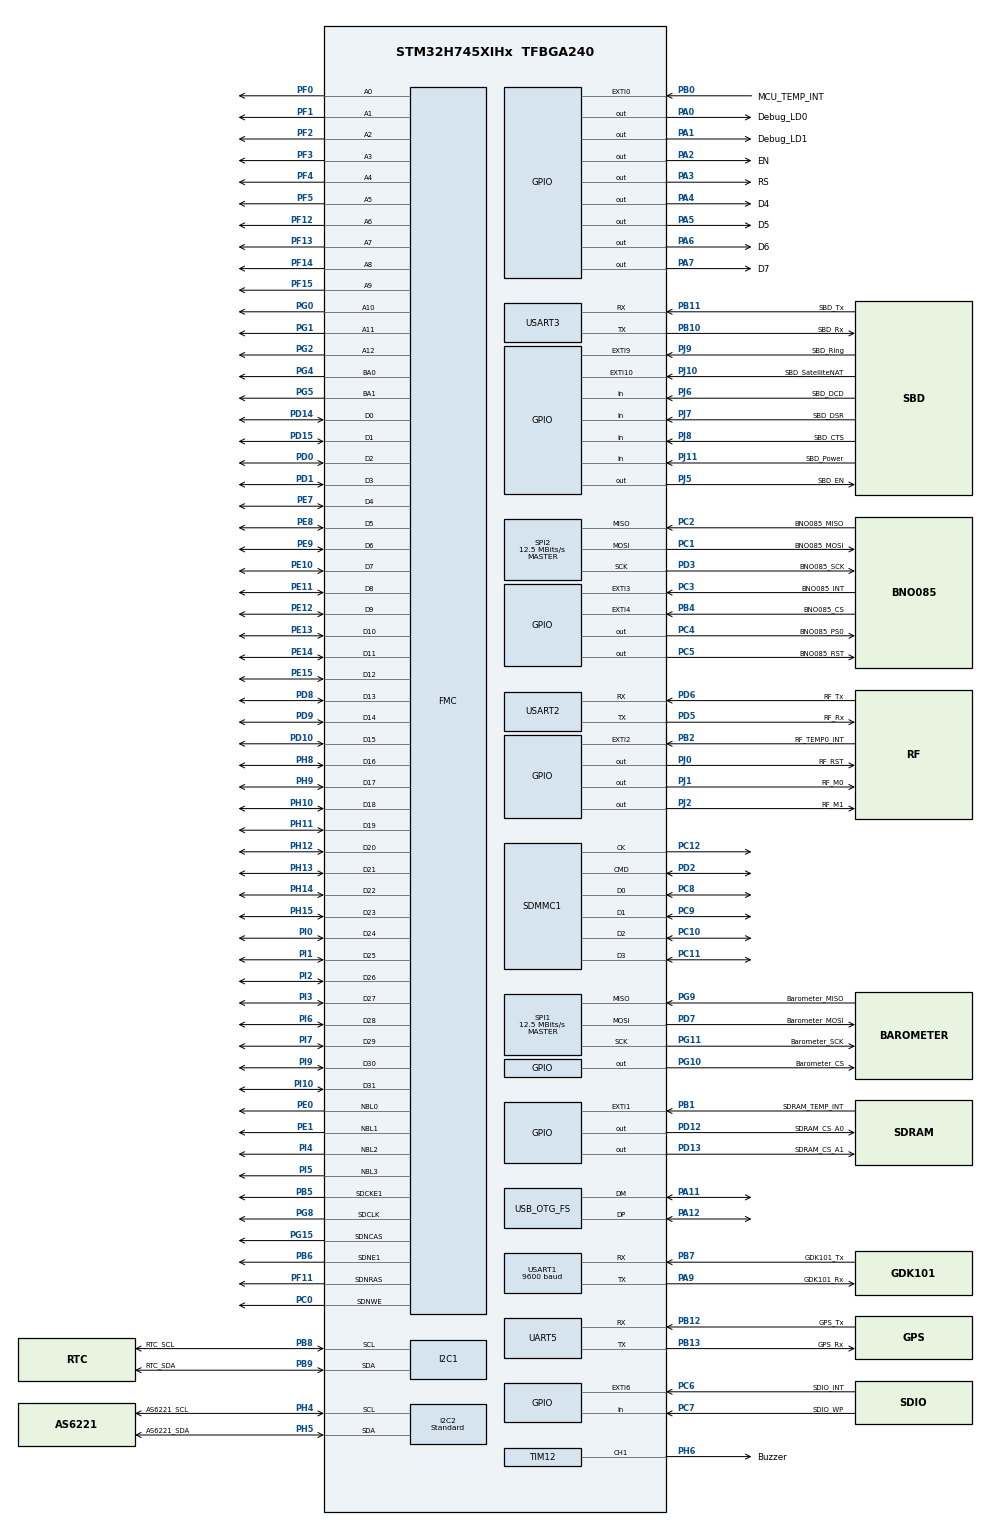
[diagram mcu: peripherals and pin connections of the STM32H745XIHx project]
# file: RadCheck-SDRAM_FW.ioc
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ADC3.Channel-0\#ChannelRegularConversion=ADC_CHANNEL_TEMPSENSOR
ADC3.ClockPrescalerADC3=ADC_CLOCK_ASYNC_DIV4
ADC3.ContinuousConvMode=ENABLE
ADC3.NbrOfConversionFlag=1
ADC3.OffsetNumber-0\#ChannelRegularConversion=ADC_OFFSET_NONE
ADC3.OffsetSignedSaturation-0\#ChannelRegularConversion=DISABLE
ADC3.Rank-0\#ChannelRegularConversion=1
ADC3.SamplingTime-0\#ChannelRegularConversion=ADC_SAMPLETIME_387CYCLES_5
CORTEX_M7.CPU_DCache=Disabled
CORTEX_M7.CPU_ICache=Disabled
CORTEX_M7.MPU_Control=__NULL
CORTEX_M7.default_mode_Activation=1
CortexM4.IPs=BDMA,CORTEX_M4\:I,DMA,FATFS_M4\:I,FREERTOS_M4\:I,GPIO,IWDG2\:I,MDMA,NVIC2\:I,OPENAMP_M4\:I,PDM2PCM_M4\:I,PWR,RCC,RESMGR_UTILITY,SYS_M4\:I,USB_DEVICE_M4\:I,USB_HOST_M4\:I,VREFBUF,WWDG2\:I
CortexM7.IPs=BDMA\:I,CORTEX_M7\:I,DMA\:I,FATFS_M7\:I,FREERTOS_M7\:I,GPIO\:I,IWDG1\:I,MDMA\:I,NVIC1\:I,OPENAMP_M7\:I,PDM2PCM_M7\:I,PWR\:I,RCC\:I,RESMGR_UTILITY\:I,SYS\:I,USB_DEVICE_M7\:I,USB_HOST_M7\:I,VREFBUF\:I,WWDG1\:I,MEMORYMAP\:I,DEBUG\:I,USART1\:I,I2C1\:I,SDMMC1\:I,USB_OTG_FS\:I,SPI2\:I,USART2\:I,SPI1\:I,I2C2\:I,FMC\:I,UART5\:I,USART3\:I,TIM12\:I,TIM1\:I,ADC3\:I
CortexM7.Pins=PA2,PA1,PA0,PJ0,PJ1,PA6,PA7,PD12,PD13,PA5,PJ2,PA3,PA4
FATFS_M7.USE_DMA_CODE_SD=1
FATFS_M7._MAX_SS=4096
FATFS_M7._USE_LFN=1
FMC.CASLatency1=FMC_SDRAM_CAS_LATENCY_3
FMC.ColumnBitsNumber1=FMC_SDRAM_COLUMN_BITS_NUM_9
FMC.ExitSelfRefreshDelay1=7
FMC.LoadToActiveDelay1=2
FMC.RCDDelay1=2
FMC.RPDelay1=2
FMC.RPDelay2=2
FMC.ReadBurst1=FMC_SDRAM_RBURST_ENABLE
FMC.ReadBurst2=FMC_SDRAM_RBURST_ENABLE
FMC.RowCycleDelay1=6
FMC.RowCycleDelay2=6
FMC.SDClockPeriod1=FMC_SDRAM_CLOCK_PERIOD_2
FMC.SDClockPeriod2=FMC_SDRAM_CLOCK_PERIOD_2
FMC.SelfRefreshTime1=5
FMC.WriteRecoveryTime1=3
I2C1.Timing=0x10C0ECFF
I2C2.I2C_Speed_Mode=I2C_Standard
I2C2.Timing=0x10C0ECFF
Mcu.Family=STM32H7
Mcu.Name=STM32H745XIHx
Mcu.Package=TFBGA240
NVIC1.OTG_FS_IRQn=true\:0\:0\:false\:false\:true\:false\:true\:true
NVIC1.PriorityGroup=NVIC_PRIORITYGROUP_4
NVIC1.SDMMC1_IRQn=true\:0\:0\:false\:true\:true\:1\:true\:true\:true
NVIC2.PriorityGroup=NVIC_PRIORITYGROUP_4
PA0.GPIO_Label=Debug_LD0
PA0.GPIO_Speed=GPIO_SPEED_FREQ_VERY_HIGH
PA0.PinAttribute=CortexM7
PA0.PinState=GPIO_PIN_SET
PA0.Signal=GPIO_Output
PA1.GPIO_Label=Debug_LD1
PA1.GPIO_Speed=GPIO_SPEED_FREQ_VERY_HIGH
PA1.PinAttribute=CortexM7
PA1.PinState=GPIO_PIN_SET
PA1.Signal=GPIO_Output
PA11.GPIO_Speed=GPIO_SPEED_FREQ_VERY_HIGH
PA11.Mode=Device_Only
PA11.PinAttribute=CortexM7
PA11.Signal=USB_OTG_FS_DM
PA12.GPIO_PuPd=GPIO_PULLUP
PA12.GPIO_Speed=GPIO_SPEED_FREQ_VERY_HIGH
PA12.Mode=Device_Only
PA12.PinAttribute=CortexM7
PA12.Signal=USB_OTG_FS_DP
PA13\ (JTMS/SWDIO).Mode=Serial_Wire
PA13\ (JTMS/SWDIO).PinAttribute=CortexM7
PA13\ (JTMS/SWDIO).Signal=DEBUG_JTMS-SWDIO
PA14\ (JTCK/SWCLK).Mode=Serial_Wire
PA14\ (JTCK/SWCLK).PinAttribute=CortexM7
PA14\ (JTCK/SWCLK).Signal=DEBUG_JTCK-SWCLK
PA2.GPIO_Label=EN
PA2.PinAttribute=CortexM7
PA2.Signal=GPIO_Output
PA3.GPIO_Label=RS
PA3.PinAttribute=CortexM7
PA3.Signal=GPIO_Output
PA4.GPIO_Label=D4
PA4.PinAttribute=CortexM7
PA4.Signal=GPIO_Output
PA5.GPIO_Label=D5
PA5.PinAttribute=CortexM7
PA5.Signal=GPIO_Output
PA6.GPIO_Label=D6
PA6.PinAttribute=CortexM7
PA6.Signal=GPIO_Output
PA7.GPIO_Label=D7
PA7.PinAttribute=CortexM7
PA7.Signal=GPIO_Output
PA9.GPIO_Label=GDK101_Rx
PA9.Mode=Asynchronous
PA9.PinAttribute=CortexM7
PA9.Signal=USART1_TX
PB0.GPIO_Label=MCU_TEMP_INT
PB0.PinAttribute=Free
PB0.Signal=GPXTI0
PB1.GPIO_Label=SDRAM_TEMP_INT
PB1.PinAttribute=Free
PB1.Signal=GPXTI1
PB10.GPIO_Label=SBD_Rx
PB10.Mode=Asynchronous
PB10.PinAttribute=CortexM7
PB10.Signal=USART3_TX
PB11.GPIO_Label=SBD_Tx
PB11.Mode=Asynchronous
PB11.PinAttribute=CortexM7
PB11.Signal=USART3_RX
PB12.GPIO_Label=GPS_Tx
PB12.Mode=Asynchronous
PB12.PinAttribute=CortexM7
PB12.Signal=UART5_RX
PB13.GPIO_Label=GPS_Rx
PB13.Mode=Asynchronous
PB13.PinAttribute=CortexM7
PB13.Signal=UART5_TX
PB2.GPIO_Label=RF_TEMP0_INT
PB2.PinAttribute=Free
PB2.Signal=GPXTI2
PB4\ (NJTRST).GPIO_Label=BNO085_CS
PB4\ (NJTRST).PinAttribute=Free
PB4\ (NJTRST).Signal=GPXTI4
PB5.Mode=SdramChipSelect2_1
PB5.PinAttribute=CortexM7
PB5.Signal=FMC_SDCKE1
PB6.Mode=SdramChipSelect2_1
PB6.PinAttribute=CortexM7
PB6.Signal=FMC_SDNE1
PB7.GPIO_Label=GDK101_Tx
PB7.Mode=Asynchronous
PB7.PinAttribute=CortexM7
PB7.Signal=USART1_RX
PB8.GPIO_Label=RTC_SCL
PB8.Mode=I2C
PB8.PinAttribute=CortexM7
PB8.Signal=I2C1_SCL
PB9.GPIO_Label=RTC_SDA
PB9.Mode=I2C
PB9.PinAttribute=CortexM7
PB9.Signal=I2C1_SDA
PC0.PinAttribute=CortexM7
PC0.Signal=FMC_SDNWE
PC1.GPIO_Label=BNO085_MOSI
PC1.Mode=Full_Duplex_Master
PC1.PinAttribute=CortexM7
PC1.Signal=SPI2_MOSI
PC10.Mode=SD_4_bits_Wide_bus
PC10.PinAttribute=CortexM7
PC10.Signal=SDMMC1_D2
PC11.Mode=SD_4_bits_Wide_bus
PC11.PinAttribute=CortexM7
PC11.Signal=SDMMC1_D3
PC12.Mode=SD_4_bits_Wide_bus
PC12.PinAttribute=CortexM7
PC12.Signal=SDMMC1_CK
PC2.GPIO_Label=BNO085_MISO
PC2.Mode=Full_Duplex_Master
PC2.PinAttribute=CortexM7
PC2.Signal=SPI2_MISO
PC3.GPIO_Label=BNO085_INT
PC3.PinAttribute=Free
PC3.Signal=GPXTI3
PC4.GPIO_Label=BNO085_PS0
PC4.PinAttribute=Free
PC4.Signal=GPIO_Output
PC5.GPIO_Label=BNO085_RST
PC5.PinAttribute=Free
PC5.Signal=GPIO_Output
PC6.GPIO_Label=SDIO_INT
PC6.PinAttribute=Free
PC6.Signal=GPXTI6
PC7.GPIO_Label=SDIO_WP
PC7.PinAttribute=Free
PC7.Signal=GPIO_Input
PC8.Mode=SD_4_bits_Wide_bus
PC8.PinAttribute=CortexM7
PC8.Signal=SDMMC1_D0
PC9.Mode=SD_4_bits_Wide_bus
PC9.PinAttribute=CortexM7
PC9.Signal=SDMMC1_D1
PD0.PinAttribute=CortexM7
PD0.Signal=FMC_D2_DA2
PD1.PinAttribute=CortexM7
PD1.Signal=FMC_D3_DA3
PD10.PinAttribute=CortexM7
PD10.Signal=FMC_D15_DA15
PD12.GPIO_Label=SDRAM_CS_A0
PD12.GPIO_Speed=GPIO_SPEED_FREQ_VERY_HIGH
PD12.PinAttribute=CortexM7
PD12.PinState=GPIO_PIN_SET
PD12.Signal=GPIO_Output
PD13.GPIO_Label=SDRAM_CS_A1
PD13.GPIO_Speed=GPIO_SPEED_FREQ_VERY_HIGH
PD13.PinAttribute=CortexM7
PD13.PinState=GPIO_PIN_SET
PD13.Signal=GPIO_Output
PD14.PinAttribute=CortexM7
PD14.Signal=FMC_D0_DA0
PD15.PinAttribute=CortexM7
PD15.Signal=FMC_D1_DA1
PD2.Mode=SD_4_bits_Wide_bus
PD2.PinAttribute=CortexM7
PD2.Signal=SDMMC1_CMD
PD3.GPIO_Label=BNO085_SCK
PD3.Mode=Full_Duplex_Master
PD3.PinAttribute=CortexM7
PD3.Signal=SPI2_SCK
PD5.GPIO_Label=RF_Rx
PD5.Mode=Asynchronous
PD5.PinAttribute=CortexM7
PD5.Signal=USART2_TX
PD6.GPIO_Label=RF_Tx
PD6.Mode=Asynchronous
PD6.PinAttribute=CortexM7
PD6.Signal=USART2_RX
PD7.GPIO_Label=Barometer_MOSI
PD7.Mode=Full_Duplex_Master
PD7.PinAttribute=CortexM7
PD7.Signal=SPI1_MOSI
PD8.PinAttribute=CortexM7
PD8.Signal=FMC_D13_DA13
PD9.PinAttribute=CortexM7
PD9.Signal=FMC_D14_DA14
PE0.PinAttribute=CortexM7
PE0.Signal=FMC_NBL0
PE1.PinAttribute=CortexM7
PE1.Signal=FMC_NBL1
PE10.PinAttribute=CortexM7
PE10.Signal=FMC_D7_DA7
PE11.PinAttribute=CortexM7
PE11.Signal=FMC_D8_DA8
PE12.PinAttribute=CortexM7
PE12.Signal=FMC_D9_DA9
PE13.PinAttribute=CortexM7
PE13.Signal=FMC_D10_DA10
PE14.PinAttribute=CortexM7
PE14.Signal=FMC_D11_DA11
PE15.PinAttribute=CortexM7
PE15.Signal=FMC_D12_DA12
PE7.PinAttribute=CortexM7
PE7.Signal=FMC_D4_DA4
PE8.PinAttribute=CortexM7
PE8.Signal=FMC_D5_DA5
PE9.PinAttribute=CortexM7
PE9.Signal=FMC_D6_DA6
PF0.PinAttribute=CortexM7
PF0.Signal=FMC_A0
PF1.PinAttribute=CortexM7
PF1.Signal=FMC_A1
PF11.PinAttribute=CortexM7
PF11.Signal=FMC_SDNRAS
PF12.PinAttribute=CortexM7
PF12.Signal=FMC_A6
PF13.PinAttribute=CortexM7
PF13.Signal=FMC_A7
PF14.PinAttribute=CortexM7
PF14.Signal=FMC_A8
PF15.PinAttribute=CortexM7
PF15.Signal=FMC_A9
PF2.PinAttribute=CortexM7
PF2.Signal=FMC_A2
PF3.PinAttribute=CortexM7
PF3.Signal=FMC_A3
PF4.PinAttribute=CortexM7
PF4.Signal=FMC_A4
PF5.PinAttribute=CortexM7
PF5.Signal=FMC_A5
PG0.PinAttribute=CortexM7
PG0.Signal=FMC_A10
PG1.PinAttribute=CortexM7
PG1.Signal=FMC_A11
PG10.GPIO_Label=Barometer_CS
PG10.PinAttribute=Free
PG10.Signal=GPIO_Output
PG11.GPIO_Label=Barometer_SCK
PG11.Mode=Full_Duplex_Master
PG11.PinAttribute=CortexM7
PG11.Signal=SPI1_SCK
PG15.PinAttribute=CortexM7
PG15.Signal=FMC_SDNCAS
PG2.PinAttribute=CortexM7
PG2.Signal=FMC_A12
PG4.PinAttribute=CortexM7
PG4.Signal=FMC_A14_BA0
PG5.PinAttribute=CortexM7
PG5.Signal=FMC_A15_BA1
PG8.PinAttribute=CortexM7
PG8.Signal=FMC_SDCLK
PG9.GPIO_Label=Barometer_MISO
PG9.Mode=Full_Duplex_Master
PG9.PinAttribute=CortexM7
PG9.Signal=SPI1_MISO
PH0-OSC_IN\ (PH0).Mode=HSE-External-Oscillator
PH0-OSC_IN\ (PH0).PinAttribute=Free
PH0-OSC_IN\ (PH0).Signal=RCC_OSC_IN
PH1-OSC_OUT\ (PH1).Mode=HSE-External-Oscillator
PH1-OSC_OUT\ (PH1).PinAttribute=Free
PH1-OSC_OUT\ (PH1).Signal=RCC_OSC_OUT
PH10.PinAttribute=CortexM7
PH10.Signal=FMC_D18
PH11.PinAttribute=CortexM7
PH11.Signal=FMC_D19
PH12.PinAttribute=CortexM7
PH12.Signal=FMC_D20
PH13.PinAttribute=CortexM7
PH13.Signal=FMC_D21
PH14.PinAttribute=CortexM7
PH14.Signal=FMC_D22
PH15.PinAttribute=CortexM7
PH15.Signal=FMC_D23
PH4.GPIO_Label=AS6221_SCL
PH4.Mode=I2C
PH4.PinAttribute=CortexM7
PH4.Signal=I2C2_SCL
PH5.GPIO_Label=AS6221_SDA
PH5.Mode=I2C
PH5.PinAttribute=CortexM7
PH5.Signal=I2C2_SDA
PH6.GPIO_Label=Buzzer
PH6.PinAttribute=CortexM7
PH6.Signal=S_TIM12_CH1
PH8.PinAttribute=CortexM7
PH8.Signal=FMC_D16
PH9.PinAttribute=CortexM7
PH9.Signal=FMC_D17
PI0.PinAttribute=CortexM7
PI0.Signal=FMC_D24
PI1.PinAttribute=CortexM7
PI1.Signal=FMC_D25
PI10.PinAttribute=CortexM7
PI10.Signal=FMC_D31
PI2.PinAttribute=CortexM7
PI2.Signal=FMC_D26
PI3.PinAttribute=CortexM7
PI3.Signal=FMC_D27
PI4.PinAttribute=CortexM7
PI4.Signal=FMC_NBL2
PI5.PinAttribute=CortexM7
PI5.Signal=FMC_NBL3
PI6.PinAttribute=CortexM7
PI6.Signal=FMC_D28
PI7.PinAttribute=CortexM7
PI7.Signal=FMC_D29
PI9.PinAttribute=CortexM7
PI9.Signal=FMC_D30
PJ0.GPIO_Label=RF_RST
PJ0.PinAttribute=CortexM7
PJ0.Signal=GPIO_Output
PJ1.GPIO_Label=RF_M0
PJ1.PinAttribute=CortexM7
PJ1.Signal=GPIO_Output
PJ10.GPIO_Label=SBD_SatelliteNAT
PJ10.PinAttribute=Free
PJ10.Signal=GPXTI10
PJ11.GPIO_Label=SBD_Power
PJ11.PinAttribute=Free
PJ11.Signal=GPIO_Input
PJ2.GPIO_Label=RF_M1
PJ2.PinAttribute=CortexM7
PJ2.Signal=GPIO_Output
PJ5.GPIO_Label=SBD_EN
PJ5.PinAttribute=Free
PJ5.Signal=GPIO_Output
PJ6.GPIO_Label=SBD_DCD
PJ6.PinAttribute=Free
PJ6.Signal=GPIO_Input
PJ7.GPIO_Label=SBD_DSR
PJ7.PinAttribute=Free
PJ7.Signal=GPIO_Input
PJ8.GPIO_Label=SBD_CTS
PJ8.PinAttribute=Free
PJ8.Signal=GPIO_Input
PJ9.GPIO_Label=SBD_Ring
PJ9.PinAttribute=Free
PJ9.Signal=GPXTI9
ProjectManager.HeapSize=M4-0x200,M7-0x200
ProjectManager.StackSize=M4-0x400,M7-0x400
ProjectManager.TargetToolchain=STM32CubeIDE
RCC.ADCFreq_Value=78000000
RCC.APB1Freq_Value=100000000
RCC.APB2Freq_Value=100000000
RCC.APB3Freq_Value=100000000
RCC.APB4Freq_Value=100000000
RCC.CortexFreq_Value=400000000
RCC.D1PPRE=RCC_APB3_DIV2
RCC.D2PPRE1=RCC_APB1_DIV2
RCC.D2PPRE2=RCC_APB2_DIV2
RCC.D3PPRE=RCC_APB4_DIV2
RCC.DIVM1=3
RCC.DIVM2=1
RCC.DIVN1=200
RCC.DIVN2=13
RCC.DIVQ1=4
RCC.HCLKFreq_Value=200000000
RCC.HPRE=RCC_HCLK_DIV2
RCC.HSE_VALUE=12000000
RCC.PLL2FRACN=0
RCC.PLL3FRACN=0
RCC.PLLFRACN=0
RCC.PLLSourceVirtual=RCC_PLLSOURCE_HSE
RCC.PWR_Regulator_Voltage_Scale=PWR_REGULATOR_VOLTAGE_SCALE0
RCC.SYSCLKFreq_VALUE=400000000
RCC.SYSCLKSource=RCC_SYSCLKSOURCE_PLLCLK
RCC.SupplySource=PWR_LDO_SUPPLY
RCC.USBCLockSelection=RCC_USBCLKSOURCE_HSI48
RCC.USBFreq_Value=48000000
SH.FMC_A0.0=FMC_A0,13b-sda1
SH.FMC_A1.0=FMC_A1,13b-sda1
SH.FMC_A10.0=FMC_A10,13b-sda1
SH.FMC_A11.0=FMC_A11,13b-sda1
SH.FMC_A12.0=FMC_A12,13b-sda1
SH.FMC_A14_BA0.0=FMC_BA0,FourSdramBanks1
SH.FMC_A15_BA1.0=FMC_BA1,FourSdramBanks1
SH.FMC_A2.0=FMC_A2,13b-sda1
SH.FMC_A3.0=FMC_A3,13b-sda1
SH.FMC_A4.0=FMC_A4,13b-sda1
SH.FMC_A5.0=FMC_A5,13b-sda1
SH.FMC_A6.0=FMC_A6,13b-sda1
SH.FMC_A7.0=FMC_A7,13b-sda1
SH.FMC_A8.0=FMC_A8,13b-sda1
SH.FMC_A9.0=FMC_A9,13b-sda1
SH.FMC_D0_DA0.0=FMC_D0,sd-32b-d1
SH.FMC_D10_DA10.0=FMC_D10,sd-32b-d1
SH.FMC_D11_DA11.0=FMC_D11,sd-32b-d1
SH.FMC_D12_DA12.0=FMC_D12,sd-32b-d1
SH.FMC_D13_DA13.0=FMC_D13,sd-32b-d1
SH.FMC_D14_DA14.0=FMC_D14,sd-32b-d1
SH.FMC_D15_DA15.0=FMC_D15,sd-32b-d1
SH.FMC_D16.0=FMC_D16,sd-32b-d1
SH.FMC_D17.0=FMC_D17,sd-32b-d1
SH.FMC_D18.0=FMC_D18,sd-32b-d1
SH.FMC_D19.0=FMC_D19,sd-32b-d1
SH.FMC_D1_DA1.0=FMC_D1,sd-32b-d1
SH.FMC_D20.0=FMC_D20,sd-32b-d1
SH.FMC_D21.0=FMC_D21,sd-32b-d1
SH.FMC_D22.0=FMC_D22,sd-32b-d1
SH.FMC_D23.0=FMC_D23,sd-32b-d1
SH.FMC_D24.0=FMC_D24,sd-32b-d1
SH.FMC_D25.0=FMC_D25,sd-32b-d1
SH.FMC_D26.0=FMC_D26,sd-32b-d1
SH.FMC_D27.0=FMC_D27,sd-32b-d1
SH.FMC_D28.0=FMC_D28,sd-32b-d1
SH.FMC_D29.0=FMC_D29,sd-32b-d1
SH.FMC_D2_DA2.0=FMC_D2,sd-32b-d1
SH.FMC_D30.0=FMC_D30,sd-32b-d1
SH.FMC_D31.0=FMC_D31,sd-32b-d1
SH.FMC_D3_DA3.0=FMC_D3,sd-32b-d1
SH.FMC_D4_DA4.0=FMC_D4,sd-32b-d1
SH.FMC_D5_DA5.0=FMC_D5,sd-32b-d1
SH.FMC_D6_DA6.0=FMC_D6,sd-32b-d1
SH.FMC_D7_DA7.0=FMC_D7,sd-32b-d1
SH.FMC_D8_DA8.0=FMC_D8,sd-32b-d1
SH.FMC_D9_DA9.0=FMC_D9,sd-32b-d1
SH.FMC_NBL0.0=FMC_NBL0,Sd4ByteEnable1
SH.FMC_NBL1.0=FMC_NBL1,Sd4ByteEnable1
SH.FMC_NBL2.0=FMC_NBL2,Sd4ByteEnable1
SH.FMC_NBL3.0=FMC_NBL3,Sd4ByteEnable1
SH.FMC_SDCLK.0=FMC_SDCLK,13b-sda1
SH.FMC_SDNCAS.0=FMC_SDNCAS,13b-sda1
SH.FMC_SDNRAS.0=FMC_SDNRAS,13b-sda1
SH.FMC_SDNWE.0=FMC_SDNWE,13b-sda1
SH.S_TIM12_CH1.0=TIM12_CH1,PWM Generation1 CH1
SPI1.BaudRatePrescaler=SPI_BAUDRATEPRESCALER_16
SPI1.CalculateBaudRate=12.5 MBits/s
SPI1.Direction=SPI_DIRECTION_2LINES
SPI1.Mode=SPI_MODE_MASTER
SPI1.VirtualType=VM_MASTER
SPI2.BaudRatePrescaler=SPI_BAUDRATEPRESCALER_16
SPI2.CalculateBaudRate=12.5 MBits/s
SPI2.Direction=SPI_DIRECTION_2LINES
SPI2.Mode=SPI_MODE_MASTER
SPI2.VirtualType=VM_MASTER
SYS.userName=SYS_M7
TIM1.Prescaler=399
TIM12.Channel-PWM\ Generation1\ CH1=TIM_CHANNEL_1
TIM12.Period=1000
TIM12.Prescaler=199
TIM12.Pulse-PWM\ Generation1\ CH1=10
USART1.BaudRate=9600
USART1.VirtualMode-Asynchronous=VM_ASYNC
USART2.VirtualMode-Asynchronous=VM_ASYNC
USART3.VirtualMode-Asynchronous=VM_ASYNC
USB_DEVICE_M7.CLASS_NAME_FS=CDC
USB_DEVICE_M7.VirtualMode-CDC_FS=Cdc
USB_DEVICE_M7.VirtualModeFS=Cdc_FS
USB_OTG_FS.VirtualMode=Device_Only
VP_ADC3_TempSens_Input.Mode=IN-TempSens
VP_FATFS_M7_VS_SDIO.Mode=SDIO
VP_MEMORYMAP_VS_MEMORYMAP.Mode=CurAppReg
VP_SYS_M4_VS_Systick.Mode=SysTick
VP_TIM12_VS_ClockSourceINT.Mode=Internal
VP_TIM1_VS_ClockSourceINT.Mode=Internal
VP_USB_DEVICE_M7_VS_USB_DEVICE_CDC_FS.Mode=CDC_FS
board=custom

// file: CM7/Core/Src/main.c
/* USER CODE BEGIN Header */
/**
  ******************************************************************************
  * @file           : main.c
  * @brief          : Main program body
  ******************************************************************************
  * @attention
  *
  * Copyright (c) 2025 STMicroelectronics.
  * All rights reserved.
  *
  * This software is licensed under terms that can be found in the LICENSE file
  * in the root directory of this software component.
  * If no LICENSE file comes with this software, it is provided AS-IS.
  *
  ******************************************************************************
  */
/* USER CODE END Header */
#include "main.h"
#include "adc.h"
#include "fatfs.h"
#include "i2c.h"
#include "memorymap.h"
#include "sdmmc.h"
#include "spi.h"
#include "tim.h"
#include "usart.h"
#include "usb_device.h"
#include "gpio.h"
#include "fmc.h"

/* USER CODE BEGIN Includes */
#include "stdio.h"
#include "string.h"
#include "stdarg.h"
#include "AS6221.h"
#include "CLCD.h"
#include "INA219.h"

/* USER CODE END Includes */

/* USER CODE BEGIN PD */
#define AS6221_MCU_ADDR 0x48 << 1
#define AS6221_SDRAM_ADDR 0x49 << 1
#define AS6221_RF1_ADDR 0x4A << 1
#define AS6221_RF2_ADDR 0x4B << 1

#define NUM_SENSORS	4

#ifndef HSEM_ID_0
#define HSEM_ID_0 (0U) /* HW semaphore 0*/
#endif

/* USER CODE END PD */

/* USER CODE BEGIN PM */
int _write(int file, char *ptr, int len){
    CDC_Transmit_FS(ptr, len);
    return (len);
}

/* USER CODE END PM */

/* USER CODE BEGIN PV */
extern SDRAM_HandleTypeDef hsdram1;
#define SDRAM_DEVICE_ADDR  ((uint32_t)0xD0000000)
#define SDRAM_DEVICE_SIZE  (0x02000000)   /* 32 MB */
#define TEST_BUF_WORDS     256

static uint32_t txBuf[TEST_BUF_WORDS];
static uint32_t rxBuf[TEST_BUF_WORDS];
/* USER CODE END PV */

void SystemClock_Config(void);
static void MX_NVIC_Init(void);

/* USER CODE BEGIN 0 */

void BSP_SDRAM_Init(void)
{
    /* 1) FMC 컨트롤러 레지스터 초기화 */
    MX_FMC_Init();

    /* 2) JEDEC 표준 전원-업 시퀀스 */
    FMC_SDRAM_CommandTypeDef cmd = {0};

    /* CLK enable */
    cmd.CommandMode            = FMC_SDRAM_CMD_CLK_ENABLE;
    cmd.CommandTarget          = FMC_SDRAM_CMD_TARGET_BANK2;
    cmd.AutoRefreshNumber      = 1;
    cmd.ModeRegisterDefinition = 0;
    HAL_SDRAM_SendCommand(&hsdram1, &cmd, HAL_MAX_DELAY);
    HAL_Delay(1);                       /* >100 µs */

    /* Precharge all */
    cmd.CommandMode = FMC_SDRAM_CMD_PALL;
    HAL_SDRAM_SendCommand(&hsdram1, &cmd, HAL_MAX_DELAY);

    /* Auto-Refresh 2회 */
    cmd.CommandMode       = FMC_SDRAM_CMD_AUTOREFRESH_MODE;
    cmd.AutoRefreshNumber = 2;
    HAL_SDRAM_SendCommand(&hsdram1, &cmd, HAL_MAX_DELAY);

    /* Mode Register 설정 (Burst=4, Sequential, CAS=3, WriteBurst=Single) */
    uint32_t mode =  (0 << 0)  |      /* Burst length = 1 → 0, 2→1, 4→2…*/
                     (0 << 3)  |      /* Sequential */
                     (3 << 4)  |      /* CAS Latency = 3 */
                     (1 << 9);        /* Write burst = single */
    cmd.CommandMode            = FMC_SDRAM_CMD_LOAD_MODE;
    cmd.ModeRegisterDefinition = mode;
    HAL_SDRAM_SendCommand(&hsdram1, &cmd, HAL_MAX_DELAY);

    /* Refresh Rate 설정 : 64 ms / 8192 rows = 7.81 µs
       → (7.81 µs × 100 MHz) – 20 = 758 */
    HAL_SDRAM_ProgramRefreshRate(&hsdram1, 758);
}

/* ② 간단한 R/W 테스트 함수 */
void SDRAM_Test(void)
{
    /* 패턴 생성 */
	uint32_t testData = 0x77777777;

    /* 32-비트 단위 Write & Read */
	HAL_SDRAM_Write_32b(&hsdram1, SDRAM_DEVICE_ADDR, &testData, SDRAM_DEVICE_SIZE / 4);
//    HAL_SDRAM_Read_32b (&hsdram1, SDRAM_DEVICE_ADDR, rxBuf, TEST_BUF_WORDS);
//
//    /* 검증 */
//    for (uint32_t i=0;i<TEST_BUF_WORDS;i++)
//    {
//        if (rxBuf[i] != txBuf[i])
//        {
//            Error_Handler();          /* 불일치 시 중단 */
//        }
//    }
}

static HAL_StatusTypeDef GDK101_Send(char cmd,
                                     const char *data,
                                     uint8_t *rx,
                                     uint16_t len,
                                     uint32_t tout_ms)
{
    /* ---------- TX ---------- */
    uint8_t tx[8];               /* 0x02 C : ? CR LF  = 6~7B */
    uint8_t i = 0;
    tx[i++] = 0x02;              /* STX '┐' */
    tx[i++] = (uint8_t)cmd;
    tx[i++] = ':';
    while (*data && i < sizeof(tx)-2) tx[i++] = (uint8_t)*data++;
    tx[i++] = 0x0D;              /* CR */
    tx[i++] = 0x0A;              /* LF */

    if (HAL_UART_Transmit(&huart1, tx, i, tout_ms) != HAL_OK)
        return HAL_ERROR;

    /* ---------- RX : < … LF > 까지 가변 길 읽기 ---------- */
    uint32_t t0 = HAL_GetTick();
    uint16_t pos = 0;
    while ((HAL_GetTick() - t0) < tout_ms)
    {
        uint8_t c;
        if (HAL_UART_Receive(&huart1, &c, 1, 10) == HAL_OK)
        {
            if (pos < len-1) rx[pos++] = c;   /* 버퍼 초과 보호 */
            if (c == 0x0A) break;             /* LF → 패킷 끝 */
        }
    }

    if (pos == 0 || rx[pos-1] != 0x0A)        /* 아무 것도 못 받음 */
        return HAL_TIMEOUT;

    rx[pos] = 0;                              /* NULL 종단 */
    return HAL_OK;
}

static void ShowDose(void)
{
    static uint8_t first = 1;
    uint8_t buf[24];
    char    line[20];
    float   dose;

    /* ── Auto-send OFF : U:0 (응답 없음 정상) ── */
    if (first) { GDK101_Send('U', "0", buf, sizeof(buf), 100); HAL_Delay(20); first = 0; }

    /* ── 1 분 평균 ── */
    if (GDK101_Send('M', "?", buf, sizeof(buf), 60) != HAL_OK) {
        lcd_setCurStr(0, 0, "UART Timeout   "); return;
    }
    char *p = (buf[0] == 0x02) ? (char*)&buf[1] : (char*)buf;  /* STX 필터 */
    if (sscanf(p, "M:%f", &dose) != 1) {
        lcd_setCurStr(0, 0, "Parse Error    "); return;
    }
    sprintf(line, "1m:%5.2f uSv/h", dose);
    lcd_setCurStr(0, 0, line);

    /* ── 10 분 평균 ── */
    if (GDK101_Send('D', "?", buf, sizeof(buf), 60) == HAL_OK) {
        p = (buf[0] == 0x02) ? (char*)&buf[1] : (char*)buf;
        if (sscanf(p, "D:%f", &dose) == 1) {
            sprintf(line, "10m:%5.2f uSv/h", dose);
            lcd_setCurStr(0, 1, line);
            return;
        }
    }
    lcd_setCurStr(0, 1, "                ");   /* 실패 시 클리어 */
}

/* ----- 설정 값 ---------------------------------------------------------- */
#define TEST_FILE_NAME   "0:/speed.bin"
#define TEST_TOTAL_BYTES (1024 * 1024)     /* 1 MiB */
#define CHUNK_BYTES      512               /* 섹터 크기(= DMA 전송 단위) */

/* ----- 전역 변수 -------------------------------------------------------- */
static uint8_t ioBuf[CHUNK_BYTES];         /* 512 B 버퍼 */
static FIL      sdFile;
static UINT     xferBytes;

/* LCD 출력 헬퍼 (row, col, printf-style) */
static void LCD_Print(uint8_t row, uint8_t col, const char *fmt, ...)
{
    static char line[32];
    va_list ap; va_start(ap, fmt);
    vsnprintf(line, sizeof(line), fmt, ap);
    va_end(ap);
    lcd_setCurStr(row, col, line);
}

/* ----- 속도 측정 함수 --------------------------------------------------- */
static float Measure_Write_Speed(void)
{
    /* 1. 새 파일 생성 */
    retSD = f_open(&sdFile, TEST_FILE_NAME, FA_CREATE_ALWAYS | FA_WRITE);
    if (retSD != FR_OK) { LCD_Print(0,0,"openW err %d", retSD); return -1.0f; }

    uint32_t start_ms = HAL_GetTick();
    uint32_t done     = 0;

    /* 2. TEST_TOTAL_BYTES 만큼 반복 기록 */
    while (done < TEST_TOTAL_BYTES)
    {
        retSD = f_write(&sdFile, ioBuf, CHUNK_BYTES, &xferBytes);
        if (retSD != FR_OK || xferBytes != CHUNK_BYTES) break;
        done += CHUNK_BYTES;
    }
    f_close(&sdFile);

    uint32_t elapsed_ms = HAL_GetTick() - start_ms;          /* 경과 시간 */
    return (done / 1024.0f) / (elapsed_ms / 1000.0f);        /* kB/s */
}

static float Measure_Read_Speed(void)
{
    /* 1. 읽기 전용으로 다시 열기 */
    retSD = f_open(&sdFile, TEST_FILE_NAME, FA_READ);
    if (retSD != FR_OK) { LCD_Print(0,0,"openR err %d", retSD); return -1.0f; }

    uint32_t start_ms = HAL_GetTick();
    uint32_t done     = 0;

    /* 2. 파일 끝까지 반복 읽기 */
    while (done < TEST_TOTAL_BYTES)
    {
        retSD = f_read(&sdFile, ioBuf, CHUNK_BYTES, &xferBytes);
        if (retSD != FR_OK || xferBytes == 0) break;
        done += xferBytes;
    }
    f_close(&sdFile);

    uint32_t elapsed_ms = HAL_GetTick() - start_ms;
    return (done / 1024.0f) / (elapsed_ms / 1000.0f);        /* kB/s */
}

/* ----- 메인 루틴 예시 --------------------------------------------------- */
void SD_SpeedTest(void)
{
    /* FatFs 마운트 */
    if ((retSD = f_mount(&SDFatFS, &SDPath[0], 1)) != FR_OK)
    { LCD_Print(0,0,"mount err %d", retSD);
      return;
    }

    /* 버퍼 초기화(패턴 채우기) */
    memset(ioBuf, 0xA5, sizeof(ioBuf));

    float w_kBps = Measure_Write_Speed();   /* 쓰기 속도 */
    float r_kBps = Measure_Read_Speed();    /* 읽기 속도 */

    if (w_kBps < 0 || r_kBps < 0) return;   /* 오류 발생 시 종료 */

    /* LCD에 결과 표시 (row, col) */
    LCD_Print(0, 0, "W:%.1f kB/s", w_kBps);
    LCD_Print(0, 1, "R:%.1f kB/s", r_kBps);
}

void SelectSdram(uint8_t sdram_num)
{
    /* 모든 칩 비활성화(HIGH) */
    HAL_GPIO_WritePin(GPIOA, GPIO_PIN_0 | GPIO_PIN_1, GPIO_PIN_SET);
    HAL_GPIO_WritePin(GPIOD, GPIO_PIN_12 | GPIO_PIN_13, GPIO_PIN_SET);

    /* 원하는 SDRAM만 LOW로 설정 */
    switch (sdram_num)
    {
        case 1:                     /* SDRAM1 → PD13 */
            HAL_GPIO_WritePin(GPIOD, GPIO_PIN_13, GPIO_PIN_RESET);
            break;

        case 2:                     /* SDRAM2 → PD12 */
            HAL_GPIO_WritePin(GPIOD, GPIO_PIN_12, GPIO_PIN_RESET);
            break;

        case 3:                     /* SDRAM3 → PA0  */
            HAL_GPIO_WritePin(GPIOA, GPIO_PIN_0,  GPIO_PIN_RESET);
            break;

        case 4:                     /* SDRAM4 → PA1  */
            HAL_GPIO_WritePin(GPIOA, GPIO_PIN_1,  GPIO_PIN_RESET);
            break;

        default:                    /* 잘못된 값 → 전부 HIGH 유지 */
            break;
    }
}
/* USER CODE END 0 */

int main(void)
{

/* USER CODE BEGIN Boot_Mode_Sequence_0 */
  int32_t timeout;
/* USER CODE END Boot_Mode_Sequence_0 */

/* USER CODE BEGIN Boot_Mode_Sequence_1 */
  /* Wait until CPU2 boots and enters in stop mode or timeout*/
//  timeout = 0xFFFF;
//  while((__HAL_RCC_GET_FLAG(RCC_FLAG_D2CKRDY) != RESET) && (timeout-- > 0));
//  if ( timeout < 0 )
//  {
//  Error_Handler();
//  }
/* USER CODE END Boot_Mode_Sequence_1 */
  /* MCU Configuration--------------------------------------------------------*/

  /* Reset of all peripherals, Initializes the Flash interface and the Systick. */
  HAL_Init();

  /* Configure the system clock */
  SystemClock_Config();
/* USER CODE BEGIN Boot_Mode_Sequence_2 */
/* When system initialization is finished, Cortex-M7 will release Cortex-M4 by means of
HSEM notification */
/*HW semaphore Clock enable*/
__HAL_RCC_HSEM_CLK_ENABLE();
/*Take HSEM */
HAL_HSEM_FastTake(HSEM_ID_0);
/*Release HSEM in order to notify the CPU2(CM4)*/
HAL_HSEM_Release(HSEM_ID_0,0);
/* wait until CPU2 wakes up from stop mode */
//timeout = 0xFFFF;
//while((__HAL_RCC_GET_FLAG(RCC_FLAG_D2CKRDY) == RESET) && (timeout-- > 0));
//if ( timeout < 0 )
//{
//Error_Handler();
//}
/* USER CODE END Boot_Mode_Sequence_2 */

  /* Initialize all configured peripherals */
  MX_GPIO_Init();
  MX_FMC_Init();
  MX_I2C1_Init();
  MX_I2C2_Init();
  MX_SDMMC1_SD_Init();
  MX_SPI1_Init();
  MX_SPI2_Init();
  MX_UART5_Init();
  MX_USART1_UART_Init();
  MX_USART2_UART_Init();
  MX_TIM12_Init();
  MX_USART3_UART_Init();
  MX_TIM1_Init();
  MX_ADC3_Init();
  MX_USB_DEVICE_Init();
  MX_FATFS_Init();

  /* Initialize interrupts */
  MX_NVIC_Init();
  /* USER CODE BEGIN 2 */
//  HAL_GPIO_WritePin(GPIOH, GPIO_PIN_4, GPIO_PIN_RESET);
//  HAL_GPIO_WritePin(GPIOH, GPIO_PIN_5, GPIO_PIN_RESET);

//  printf("Boot..!\n");

  HAL_TIM_PWM_Start(&htim12, TIM_CHANNEL_1);

  __HAL_TIM_SET_AUTORELOAD(&htim12, 999);
  __HAL_TIM_SET_COMPARE (&htim12, TIM_CHANNEL_1, 499);
  HAL_Delay(150);

  HAL_TIM_PWM_Stop(&htim12, TIM_CHANNEL_1);

  char str[16] = "choi hee soo gay";

//  printf("Boot\n");
//  HAL_Delay(2000);
//
//  uint8_t str[30];
//  lcd_Init(20, 4);
//  lcd_clear();
//
//  SelectSdram(1);
//
//  BSP_SDRAM_Init();       /* 위 시퀀스 호출 */
//
//  SDRAM_Test();           /* 메모리 검증 */
//
//  SelectSdram(2);
//
//  BSP_SDRAM_Init();       /* 위 시퀀스 호출 */
//
//  SDRAM_Test();           /* 메모리 검증 */
//
//  SelectSdram(3);
//
//  BSP_SDRAM_Init();       /* 위 시퀀스 호출 */
//
//  SDRAM_Test();           /* 메모리 검증 */
//
//  SelectSdram(4);
//
//  BSP_SDRAM_Init();       /* 위 시퀀스 호출 */
//
//  SDRAM_Test();           /* 메모리 검증 */
//
//  BYTE buf[32] = "Hello world";
//  uint32_t bw, br;
//
//  if((retSD = f_mount(&SDFatFS, &SDPath[0], 1)) == FR_OK) {
//	  sprintf(str, "f_mount OK %d", retSD);
//	  lcd_setCurStr(0, 0, str);
//  }
//  else {
//	  sprintf(str, "f_mount Failed %d", retSD);
//	  lcd_setCurStr(0, 0, str);
//  }
//
//  if((retSD = f_open(&SDFile, "0:/jmh.txt", FA_CREATE_NEW | FA_WRITE)) == FR_OK) {
//	  sprintf(buf, "Hello world");
//	  f_write(&SDFile, buf, sizeof(buf), &bw);
//
//	  sprintf(str, "%d bytes", bw);
//	  lcd_setCurStr(0, 1, str);
//
//	  f_close(&SDFile);
//  }
//  else {
//	  sprintf(str, "error %d", retSD);
//	  lcd_setCurStr(0, 0, str);
//  }

//  INA219_t ina219;
//
//  // INA219 센서 초기화
//  if (INA219_Init(&ina219, &hi2c1, INA219_ADDRESS) != 1) {
//      lcd_setCurStr(0, 0, "INA219 Init FAIL");
//      sprintf(str, "I2C Error: %lu", HAL_I2C_GetError(&hi2c1));
//      lcd_setCurStr(0, 1, str);
//      while(1); // 에러 발생시 멈춤
//  }
//
//  lcd_setCurStr(0, 0, "INA219 Init PASS!");
//  HAL_Delay(2000);
//  lcd_clear();

  lcd_Init(20, 4);

  AS6221_t as6221[NUM_SENSORS];

  as6221[0].address = AS6221_MCU_ADDR;
  as6221[0].CR = ConvPer125ms;
  as6221[0].CF = Quadruple;
  as6221[0].SM = false;
  as6221[0].IM = false;
  as6221[0].POL = false;
  as6221[0].SS = false;

  as6221[1] = as6221[0];
  as6221[2] = as6221[0];

  as6221[1].address = AS6221_SDRAM_ADDR;
  as6221[2].address = AS6221_RF1_ADDR;
  as6221[3].address = AS6221_RF2_ADDR;

  for (int i = 0; i < NUM_SENSORS; i++) {
	  if (AS6221_Init(&as6221[i]) != AS6221_ERROR_NONE) {
		  sprintf(str, "Failed Init %d", i + 1);
		  lcd_setCurStr(0, i, str);
		  sprintf(str, "Error Code: %d", AS6221_GetLastError());
		  lcd_setCurStr(0, 3, str);
	  }
  }

  HAL_Delay(2000);
  lcd_clear();

//  SD_SpeedTest();
//  HAL_Delay(1000);

//  lcd_Init(20, 4);
//  lcd_clear();
//
//  uint8_t str[30];
//
//  BYTE buf[32] = " Hello world";
//  uint32_t bw, br;
//
//  if((retSD = f_mount(&SDFatFS, &SDPath[0], 1)) == FR_OK) {
//	  sprintf(str, "f_mount OK %d", retSD);
//	  lcd_setCurStr(0, 0, str);
//  }
//  else {
//	  sprintf(str, "f_mount Failed %d", retSD);
//	  lcd_setCurStr(0, 0, str);
//  }

//  uint8_t str[20];
//  lcd_Init(20, 4);
//  lcd_clear();
//
//  for(int i = 0; i < 4; i++) {
//	  SelectSdram(i + 1);
//	  lcd_clear();
//	  sprintf(str, "CS: %d", i + 1);
//	  lcd_setCurStr(0, 0, str);
//	  HAL_Delay(3000);
//  }

  char a = "\n";
  HAL_GPIO_WritePin(RF_RST_GPIO_Port, RF_RST_Pin, GPIO_PIN_RESET);
  HAL_Delay(1000);

  HAL_GPIO_WritePin(RF_RST_GPIO_Port, RF_RST_Pin, GPIO_PIN_SET);
  HAL_Delay(1000);

  HAL_GPIO_WritePin(RF_M0_GPIO_Port, RF_M0_Pin, GPIO_PIN_RESET);
  HAL_GPIO_WritePin(RF_M1_GPIO_Port, RF_M1_Pin, GPIO_PIN_RESET);
  /* USER CODE END 2 */

  /* Infinite loop */
  /* USER CODE BEGIN WHILE */
  while (1)
  {
	  for(int i = 0; i < 16; i++)
		  HAL_UART_Transmit(&huart2, str[i], 1, 100);

	  HAL_UART_Transmit(&huart2, &a, 1, 100);
//      ShowDose();             /* 1 초마다 센서 값 표시 */
//      HAL_Delay(1000);

//      uint16_t voltage = INA219_ReadBusVoltage(&ina219);
//      int16_t current = INA219_ReadCurrent(&ina219);
//      uint16_t power = INA219_ReadPower(&ina219);
//
//      sprintf(str, "V: %2.3fV  I: %3dmA", (voltage / 1000.0) + 0.2871, current);
//      lcd_setCurStr(0, 0, str);
//      sprintf(str, "P: %4dmW", power);
//      lcd_setCurStr(0, 1, str);
//
//
//      HAL_ADC_Start(&hadc3);
//      HAL_ADC_PollForConversion(&hadc3, 100);
//      uint32_t raw = HAL_ADC_GetValue(&hadc3);
//      double temp = __HAL_ADC_CALC_TEMPERATURE(3300, raw, LL_ADC_RESOLUTION_16B);
//
//      sprintf(str, "CPU Temp: %.2fC", temp);
//	  lcd_setCurStr(0, 2, str);
//
//	  printf("Test Power: %dmW\n", power);
//
//      HAL_Delay(1000); // 1초마다 갱신
//
	  for (int i = 0; i < NUM_SENSORS; i++)
	  {
		  if (!AS6221_ReadTemperature(&as6221[i]))
		  {
			  sprintf(str, "Sensor %d Error", i + 1);
			  lcd_setCurStr(0, 0, str);
			  HAL_Delay(100);
		  }
	  }

	  sprintf(str, "MCU: %.3f", as6221[0].Temp);
	  lcd_setCurStr(0, 0, str);

	  sprintf(str, "SDRAM: %.3f", as6221[1].Temp);
	  lcd_setCurStr(0, 1, str);

	  sprintf(str, "RF Module1: %.3f", as6221[2].Temp);
	  lcd_setCurStr(0, 2, str);

	  sprintf(str, "RF Module2: %.3f", as6221[3].Temp);
	  lcd_setCurStr(0, 3, str);

	  HAL_Delay(1000);

//
//	  HAL_Delay(2500);
//
//	  HAL_GPIO_WritePin(GPIOD, GPIO_PIN_12, GPIO_PIN_RESET);
//	  HAL_GPIO_WritePin(GPIOD, GPIO_PIN_13, GPIO_PIN_SET);
//
//	  HAL_Delay(2500);
//
//	  HAL_GPIO_WritePin(GPIOD, GPIO_PIN_12, GPIO_PIN_SET);
//	  HAL_GPIO_WritePin(GPIOD, GPIO_PIN_13, GPIO_PIN_RESET);
//
//	  HAL_Delay(2500);
//
//	  HAL_GPIO_WritePin(GPIOD, GPIO_PIN_12, GPIO_PIN_SET);
//	  HAL_GPIO_WritePin(GPIOD, GPIO_PIN_13, GPIO_PIN_SET);
//
//	  HAL_Delay(2500);
    /* USER CODE END WHILE */

  }
}

void SystemClock_Config(void)
{
  RCC_OscInitTypeDef RCC_OscInitStruct = {0};
  RCC_ClkInitTypeDef RCC_ClkInitStruct = {0};

  /** Supply configuration update enable
  */
  HAL_PWREx_ConfigSupply(PWR_LDO_SUPPLY);

  /** Configure the main internal regulator output voltage
  */
  __HAL_PWR_VOLTAGESCALING_CONFIG(PWR_REGULATOR_VOLTAGE_SCALE0);

  while(!__HAL_PWR_GET_FLAG(PWR_FLAG_VOSRDY)) {}

  /** Initializes the RCC Oscillators according to the specified parameters
  * in the RCC_OscInitTypeDef structure.
  */
  RCC_OscInitStruct.OscillatorType = RCC_OSCILLATORTYPE_HSI48|RCC_OSCILLATORTYPE_HSE;
  RCC_OscInitStruct.HSEState = RCC_HSE_ON;
  RCC_OscInitStruct.HSI48State = RCC_HSI48_ON;
  RCC_OscInitStruct.PLL.PLLState = RCC_PLL_ON;
  RCC_OscInitStruct.PLL.PLLSource = RCC_PLLSOURCE_HSE;
  RCC_OscInitStruct.PLL.PLLM = 3;
  RCC_OscInitStruct.PLL.PLLN = 200;
  RCC_OscInitStruct.PLL.PLLP = 2;
  RCC_OscInitStruct.PLL.PLLQ = 4;
  RCC_OscInitStruct.PLL.PLLR = 2;
  RCC_OscInitStruct.PLL.PLLRGE = RCC_PLL1VCIRANGE_2;
  RCC_OscInitStruct.PLL.PLLVCOSEL = RCC_PLL1VCOWIDE;
  RCC_OscInitStruct.PLL.PLLFRACN = 0;
  if (HAL_RCC_OscConfig(&RCC_OscInitStruct) != HAL_OK)
  {
    Error_Handler();
  }

  /** Initializes the CPU, AHB and APB buses clocks
  */
  RCC_ClkInitStruct.ClockType = RCC_CLOCKTYPE_HCLK|RCC_CLOCKTYPE_SYSCLK
                              |RCC_CLOCKTYPE_PCLK1|RCC_CLOCKTYPE_PCLK2
                              |RCC_CLOCKTYPE_D3PCLK1|RCC_CLOCKTYPE_D1PCLK1;
  RCC_ClkInitStruct.SYSCLKSource = RCC_SYSCLKSOURCE_PLLCLK;
  RCC_ClkInitStruct.SYSCLKDivider = RCC_SYSCLK_DIV1;
  RCC_ClkInitStruct.AHBCLKDivider = RCC_HCLK_DIV2;
  RCC_ClkInitStruct.APB3CLKDivider = RCC_APB3_DIV2;
  RCC_ClkInitStruct.APB1CLKDivider = RCC_APB1_DIV2;
  RCC_ClkInitStruct.APB2CLKDivider = RCC_APB2_DIV2;
  RCC_ClkInitStruct.APB4CLKDivider = RCC_APB4_DIV2;

  if (HAL_RCC_ClockConfig(&RCC_ClkInitStruct, FLASH_LATENCY_2) != HAL_OK)
  {
    Error_Handler();
  }
}

/**
  * @brief NVIC Configuration.
  * @retval None
  */
static void MX_NVIC_Init(void)
{
  /* SDMMC1_IRQn interrupt configuration */
  HAL_NVIC_SetPriority(SDMMC1_IRQn, 0, 0);
  HAL_NVIC_EnableIRQ(SDMMC1_IRQn);
}

void Error_Handler(void)
{
  __disable_irq();
  while (1)
  {
  }
}
